# N32H7xx register map
Vendor: Nationstech Ltd.; File version: 1.0
Registers are 32-bit, read-write, reset 0x0 unless marked. A register's access mark holds for its fields unless they carry their own. Offsets are from the block's base; [hi:lo] are bit positions; {n}, {i} and the like mark numbered series.

## DSI_HOST — DSI Host Controller registers
Base 0x50000000
0x00 DSI_NUMLANES
  [3:0] NUMLANES
0x04 DSI_CONTHSCLK
  [0] CONTHSCLK
0x08 DSI_TPRE
  [7:0] TPRE
0x0C DSI_TPOST
  [7:0] TPOST
0x10 DSI_TXGAP
  [7:0] TXGAP
0x14 DSI_AUTOINSERT_EOTP
  [0] AUTOINSEOTP
0x18 DSI_DISRXCRCCHK
  [0] DISRXCRCCHK
0x1C DSI_HSTXTOCNT
  [23:0] HSTXTOCNT
0x20 DSI_LRXTOCNT
  [23:0] LRXTOCNT
0x24 DSI_BTATOCNT
  [23:0] BTATOCNT
0x28 DSI_TWAKEUP
  [18:0] TWAKEUP
0x2C DSI_DISBST
  [0] DISBST
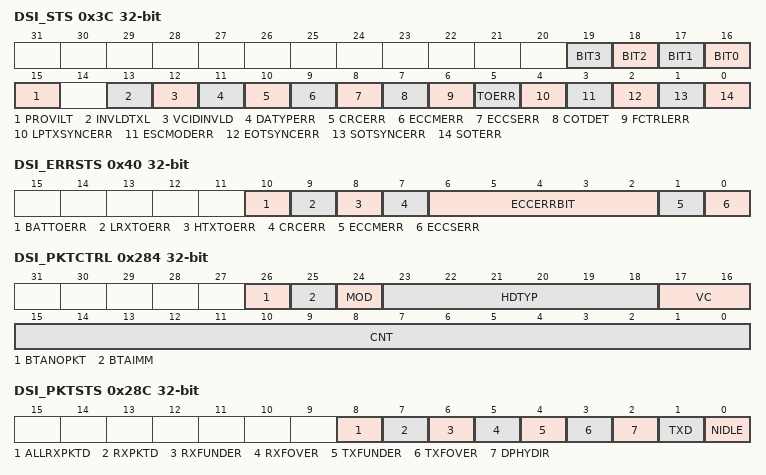
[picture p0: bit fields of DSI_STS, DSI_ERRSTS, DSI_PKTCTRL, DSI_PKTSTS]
0x3C DSI_STS
  [n+16] BIT{n} (n=0..3), [15] PROVILT, [13] INVLDTXL, [12] VCIDINVLD, [11] DATYPERR, [10] CRCERR, [9] ECCMERR, [8] ECCSERR, [7] COTDET, [6] FCTRLERR, [5] TOERR, [4] LPTXSYNCERR, [3] ESCMODERR, [2] EOTSYNCERR, [1] SOTSYNCERR, [0] SOTERR
0x40 DSI_ERRSTS
  [10] BATTOERR, [9] LRXTOERR, [8] HTXTOERR, [7] CRCERR, [6:2] ECCERRBIT, [1] ECCMERR, [0] ECCSERR
0x60 DSI_CLKLANEN
  [0] CLKLANEN
0x64 DSI_DATLANEN
  [3:0] DATLANEN
0xC0 DSI_SKEWCALTIMI
  [15:0] SKEWCALTIMI
0xC4 DSI_SKEWCALTIMP
  [15:0] SKEWCALTIMP
0xC8 DSI_ALTCALTIM
  [15:0] ALTCALTIM
0xCC VID_SKEWCALINE
  [7:0] SKEWCALINE
0x200 VID_EN
  [0] EN
0x204 VID_PIXPERPKT
  [15:0] PIXPERPKT
0x208 VID_PIXPLDSIZ
  [15:0] PIXPLDSIZ
0x20C VID_PIXALIGN
  [0] PIXALIGN
0x210 VID_PIXFMT
  [5:0] PIXFMT
0x214 VID_VSYNCPOL
  [0] VSYNCPOL
0x218 VID_HSYNCPOL
  [0] HSYNCPOL
0x21C VID_VIDEOMOD
  [1:0] VIDEOMOD
0x220 VID_OVERIDE
  [0] OVERIDE
0x224 VID_STD
  [15:0] STD
0x228 VID_HFP
  [15:0] HFP
0x22C VID_HBP
  [15:0] HBP
0x230 VID_HSA
  [15:0] HAS
0x234 VID_PKTPERLINE reset 0x1
  [3:0] PKTPERLINE
0x238 VID_VBP
  [15:0] VBP
0x23C VID_VFP
  [15:0] VFP
0x240 VID_BLLPMOD
  [0] BLLPMOD
0x244 VID_NULLPKTBLLP
  [0] NULLPKTBLLP
0x248 VID_VACT
  [15:0] VACT
0x24C VID_VC
  [1:0] VC
0x250 VID_EXTPKTEN
  [3:0] EXTPKTEN
0x254 VID_VSSPLD
  [15:0] VSSPLD
0x258 VID_PLDPERPKT
  [15:0] PLDPERPKT
0x280 DSI_TXPLD
0x284 DSI_PKTCTRL
  [26] BTANOPKT, [25] BTAIMM, [24] MOD, [23:18] HDTYP, [17:16] VC, [15:0] CNT
0x288 DSI_SENDPKT
  [0] SENDPKT
0x28C DSI_PKTSTS
  [8] ALLRXPKTD, [7] RXPKTD, [6] RXFUNDER, [5] RXFOVER, [4] TXFUNDER, [3] TXFOVER, [2] DPHYDIR, [1] TXD, [0] NIDLE
0x290 DSI_PKTFWRLVL
  [15:0] PKTFWRLVL
0x294 DSI_PKTFRDLVL
  [15:0] PKTFRDLVL
0x298 DSI_PKTRXPLD
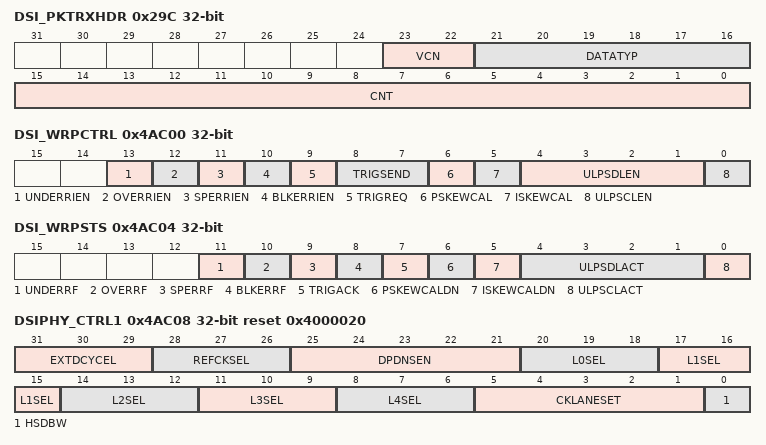
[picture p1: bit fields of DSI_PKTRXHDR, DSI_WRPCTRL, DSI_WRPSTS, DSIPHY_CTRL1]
0x29C DSI_PKTRXHDR
  [23:22] VCN, [21:16] DATATYP, [15:0] CNT
0x2B0 DSI_IFPRIOSEL
  [0] IFPRIOSEL
0x4AC00 DSI_WRPCTRL
  [13] UNDERRIEN, [12] OVERRIEN, [11] SPERRIEN, [10] BLKERRIEN, [9] TRIGREQ, [8:7] TRIGSEND, [6] PSKEWCAL, [5] ISKEWCAL, [4:1] ULPSDLEN, [0] ULPSCLEN
0x4AC04 DSI_WRPSTS
  [11] UNDERRF, [10] OVERRF, [9] SPERRF, [8] BLKERRF, [7] TRIGACK, [6] PSKEWCALDN, [5] ISKEWCALDN, [4:1] ULPSDLACT, [0] ULPSCLACT
0x4AC08 DSIPHY_CTRL1 reset 0x4000020
  [31:29] EXTDCYCEL, [28:26] REFCKSEL, [25:21] DPDNSEN, [20-3n:18-3n] L{n}SEL (n=0..4), [5:1] CKLANESET, [0] HSDBW
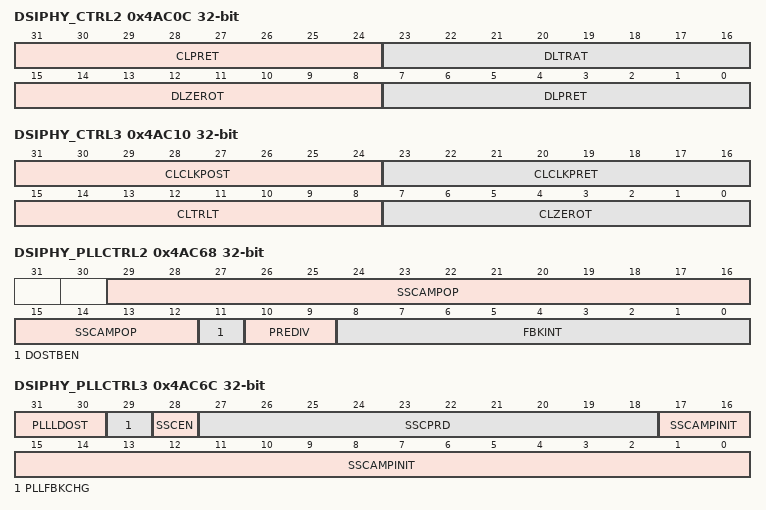
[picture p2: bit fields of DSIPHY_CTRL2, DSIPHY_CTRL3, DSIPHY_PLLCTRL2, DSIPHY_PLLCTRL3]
0x4AC0C DSIPHY_CTRL2
  [31:24] CLPRET, [23:16] DLTRAT, [15:8] DLZEROT, [7:0] DLPRET
0x4AC10 DSIPHY_CTRL3
  [31:24] CLCLKPOST, [23:16] CLCLKPRET, [15:8] CLTRLT, [7:0] CLZEROT
0x4AC14 DSIPHY_CTRL4
  [4:0] VCTRL
0x4AC64 DSIPHY_PLLCTRL1
  [23:0] PLLFBKFRA
0x4AC68 DSIPHY_PLLCTRL2
  [29:12] SSCAMPOP, [11] DOSTBEN, [10:9] PREDIV, [8:0] FBKINT
0x4AC6C DSIPHY_PLLCTRL3
  [31:30] PLLLDOST, [29] PLLFBKCHG, [28] SSCEN, [27:18] SSCPRD, [17:0] SSCAMPINIT
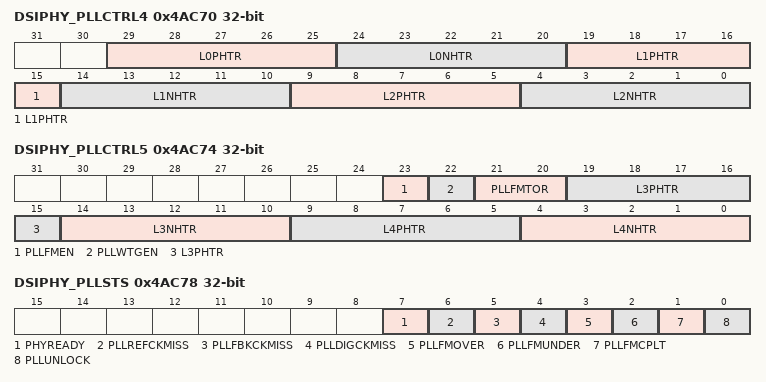
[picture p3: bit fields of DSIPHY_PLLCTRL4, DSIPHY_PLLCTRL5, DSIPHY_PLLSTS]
0x4AC70 DSIPHY_PLLCTRL4
  [29:25] L0PHTR, [24:20] L0NHTR, [19:15] L1PHTR, [14:10] L1NHTR, [9:5] L2PHTR, [4:0] L2NHTR
0x4AC74 DSIPHY_PLLCTRL5
  [23] PLLFMEN, [22] PLLWTGEN, [21:20] PLLFMTOR, [19:15] L3PHTR, [14:10] L3NHTR, [9:5] L4PHTR, [4:0] L4NHTR
0x4AC78 DSIPHY_PLLSTS
  [7] PHYREADY, [6] PLLREFCKMISS, [5] PLLFBKCKMISS, [4] PLLDIGCKMISS, [3] PLLFMOVER, [2] PLLFMUNDER, [1] PLLFMCPLT, [0] PLLUNLOCK

## I2C1 — Inter-Integrated Circuit interface
Base 0x4000E800
Same registers: I2C2 0x4000EC00, I2C3 0x4000F000, I2C4 0x400DD400, I2C5 0x400DD800, I2C6 0x400DDC00, I2C7 0x58003000, I2C8 0x58003400, I2C9 0x58003800, I2C10 0x58003C00
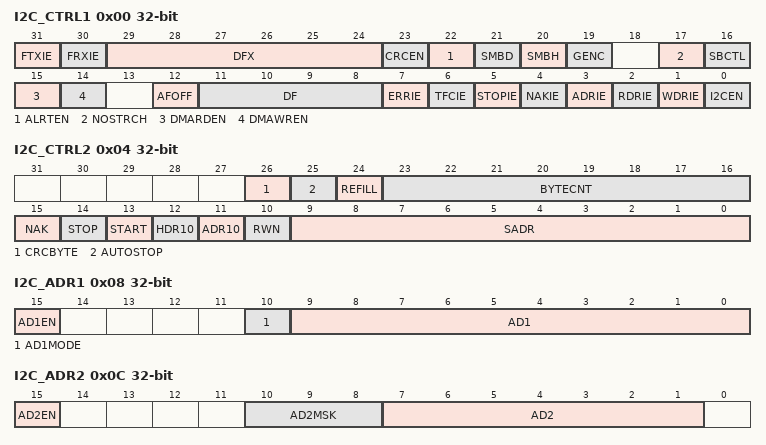
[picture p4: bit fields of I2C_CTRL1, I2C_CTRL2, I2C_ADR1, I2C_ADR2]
0x00 I2C_CTRL1 — I2C configuration register 1
  [31] FTXIE, [30] FRXIE, [29:24] DFX, [23] CRCEN, [22] ALRTEN, [21] SMBD, [20] SMBH, [19] GENC, [17] NOSTRCH, [16] SBCTL, [15] DMARDEN, [14] DMAWREN, [12] AFOFF, [11:8] DF, [7] ERRIE, [6] TFCIE, [5] STOPIE, [4] NAKIE, [3] ADRIE, [2] RDRIE, [1] WDRIE, [0] I2CEN
0x04 I2C_CTRL2 — I2C configuration register 2
  [26] CRCBYTE, [25] AUTOSTOP, [24] REFILL, [23:16] BYTECNT, [15] NAK, [14] STOP, [13] START, [12] HDR10, [11] ADR10, [10] RWN, [9:0] SADR
0x08 I2C_ADR1 — I2C own address 1 register
  [15] AD1EN, [10] AD1MODE, [9:0] AD1
0x0C I2C_ADR2 — I2C own address 2 register
  [15] AD2EN, [10:8] AD2MSK, [7:1] AD2
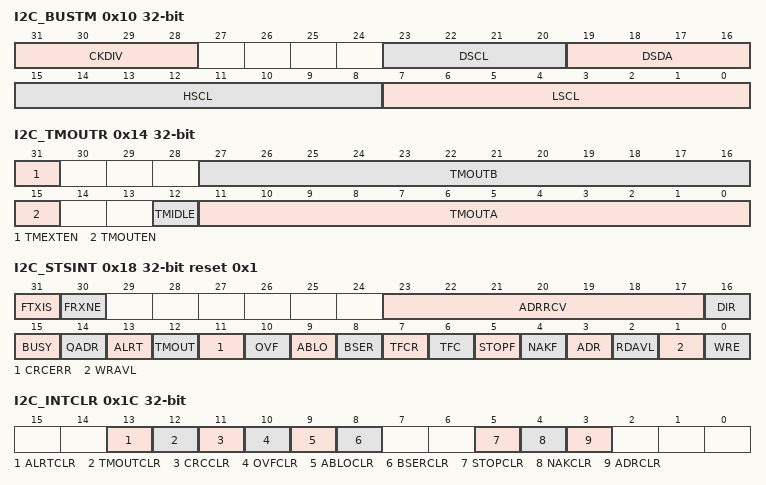
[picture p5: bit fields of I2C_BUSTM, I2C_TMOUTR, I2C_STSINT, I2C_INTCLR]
0x10 I2C_BUSTM — I2C timing register
  [31:28] CKDIV, [23:20] DSCL, [19:16] DSDA, [15:8] HSCL, [7:0] LSCL
0x14 I2C_TMOUTR — I2C timeout register
  [31] TMEXTEN, [27:16] TMOUTB, [15] TMOUTEN, [12] TMIDLE, [11:0] TMOUTA
0x18 I2C_STSINT reset 0x1 — I2C interrupt and status register
  [31] FTXIS, [30] FRXNE, [23:17] ADRRCV, [16] DIR, [15] BUSY, [14] QADR, [13] ALRT, [12] TMOUT, [11] CRCERR, [10] OVF, [9] ABLO, [8] BSER, [7] TFCR, [6] TFC, [5] STOPF, [4] NAKF, [3] ADR, [2] RDAVL, [1] WRAVL, [0] WRE
0x1C I2C_INTCLR — I2C interrupt clear register
  [13] ALRTCLR, [12] TMOUTCLR, [11] CRCCLR, [10] OVFCLR, [9] ABLOCLR, [8] BSERCLR, [5] STOPCLR, [4] NAKCLR, [3] ADRCLR
0x20 I2C_CRCR — I2C CRC register
  [7:0] CRC
0x24 I2C_RDR — I2C receive data register
  [7:0] RDAT
0x28 I2C_WDR — I2C transmit data register
  [7:0] WDAT
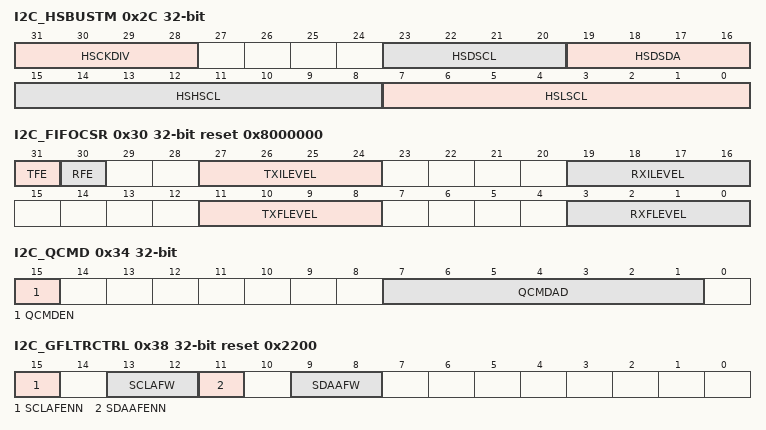
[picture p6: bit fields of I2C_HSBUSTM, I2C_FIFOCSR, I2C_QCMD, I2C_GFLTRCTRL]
0x2C I2C_HSBUSTM — I2C HS timing register
  [31:28] HSCKDIV, [23:20] HSDSCL, [19:16] HSDSDA, [15:8] HSHSCL, [7:0] HSLSCL
0x30 I2C_FIFOCSR reset 0x8000000 — I2C FIFO Control & Status register
  [31] TFE, [30] RFE, [27:24] TXILEVEL, [19:16] RXILEVEL, [11:8] TXFLEVEL, [3:0] RXFLEVEL
0x34 I2C_QCMD — I2C quick command address register
  [15] QCMDEN, [7:1] QCMDAD
0x38 I2C_GFLTRCTRL reset 0x2200 — I2C Analog noise filter register
  [15] SCLAFENN, [13:12] SCLAFW, [11] SDAAFENN, [9:8] SDAAFW
